# RZ/A1H register map
Vendor: Renesas
Registers are 32-bit, read-write, reset 0x0 unless marked. A register's access mark holds for its fields unless they carry their own. Offsets are from the block's base; [hi:lo] are bit positions; {n}, {i} and the like mark numbered series.

## OSTM0
Base 0xFCFEC000
Same registers: OSTM1 0xFCFEC400
0x00 CMP — OSTMnCMP
0x04 CNT — OSTMnCNT
0x10 TE 8-bit — OSTMnTE
  [0] TE
    0=DISABLE (Counter disabled); 1=ENABLE (Counter enabled)
0x14 TS 8-bit — OSTMnTS
  [0] TS
    0=NOP (No effect); 1=START (Starts the counter and sets TE = 1)
0x18 TT 8-bit — OSTMnTT
  [0] TT
    0=NOP (No effect); 1=STOP (Stops the counter and clears the TE bit)
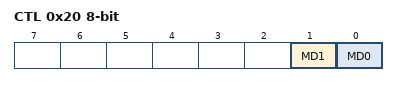
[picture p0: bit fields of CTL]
0x20 CTL 8-bit — OSTMnCTL
  [1] MD1
    0=INTERVAL_TIMER (Interval timer mode); 1=FREE_RUNNING_COMPARISON (Free-running comparison mode)
  [0] MD0

## PFV0
Base 0xE8205000
Same registers: PFV1 0xE8205800
0x00 PFVCR
0x04 PFVICR
0x08 PFVISR
{0x20+4i} PFVID{i} (i=0..7)
{0x40+4i} PFVOD{i} (i=0..7)
0x64 PFVIFSR
0x68 PFVOFSR
0x6C PFVACR
0x70 PFV_MTX_MODE
0x74 PFV_MTX_YG_ADJ0
0x78 PFV_MTX_YG_ADJ1
0x7C PFV_MTX_CBB_ADJ0
0x80 PFV_MTX_CBB_ADJ1
0x84 PFV_MTX_CRR_ADJ0
0x88 PFV_MTX_CRR_ADJ1
0x8C PFVSZR

## PWM
Base 0xFCFF5004
0x02 PWBTCR 8-bit
0xDC PWCR_1 8-bit
0xE0 PWPR_1 8-bit
0xE2 PWCYR_1 16-bit
0xE4 PWBFR_1A 16-bit
0xE6 PWBFR_1C 16-bit
0xE8 PWBFR_1E 16-bit
0xEA PWBFR_1G 16-bit
0xEC PWCR_2 8-bit
0xF0 PWPR_2 8-bit
0xF2 PWCYR_2 16-bit
0xF4 PWBFR_2A 16-bit
0xF6 PWBFR_2C 16-bit
0xF8 PWBFR_2E 16-bit
0xFA PWBFR_2G 16-bit

## RIIC0
Base 0xFCFEE000
Same registers: RIIC1 0xFCFEE400, RIIC2 0xFCFEE800, RIIC3 0xFCFEEC00
0x00 CR1 — RIICnCR1
0x04 CR2 — RIICnCR2
{0x4+4i} MR{i} (i=1..3) — RIICnMR{i}
0x14 FER — RIICnFER
0x18 SER — RIICnSER
0x1C IER — RIICnIER
0x20 SR1 — RIICnSR1
0x24 SR2 — RIICnSR2
{0x28+4i} SAR{i} (i=0..2) — RIICnSAR{i}
0x34 BRL — RIICnBRL
0x38 BRH — RIICnBRH
0x3C DRT — RIICnDRT
0x40 DRR — RIICnDRR

## ROMDEC
Base 0xE8005000
0x00 CROMEN 8-bit
0x01 CROMSY0 8-bit
0x02 CROMCTL0 8-bit
0x03 CROMCTL1 8-bit
{0x2+i} CROMCTL{i} 8-bit (i=3..5)
0x08 CROMST0 8-bit
0x09 CROMST1 8-bit
{0x8+i} CROMST{i} 8-bit (i=3..6)
{0x14+i} CBUFST{i} 8-bit (i=0..2)
{0x18+i} HEAD{i:02} 8-bit (i=0..3)
{0x1C+i} SHEAD{i:02} 8-bit (i=0..7)
{0x10+i} HEAD{i} 8-bit (i=20..23)
{0x14+i} SHEAD{i} 8-bit (i=20..27)
{0x40+i} CBUFCTL{i} 8-bit (i=0..3)
0x45 CROMST0M 8-bit
0x100 RST 8-bit — ROMDECRST
0x101 RSTSTAT 8-bit
0x102 SSI 8-bit
0x108 INTHOLD 8-bit
0x109 INHINT 8-bit
0x200 STRMDIN0 16-bit
0x202 STRMDIN2 16-bit
0x204 STRMDOUT0 16-bit

## RSCAN0
Base 0xE803A000
{0x0+0x10*i} C{i}CFG (i=0..4)
{0x4+0x10*i} C{i}CTR (i=0..4)
{0x8+0x10*i} C{i}STS (i=0..4)
{0xC+0x10*i} C{i}ERFL (i=0..4)
0x84 GCFG
0x88 GCTR
0x8C GSTS
0x90 GERFL
0x94 GTSC
0x98 GAFLECTR
0x9C GAFLCFG0
0xA0 GAFLCFG1
0xA4 RMNB
{0xA8+4i} RMND{i} (i=0..2)
{0xB8+4i} RFCC{i} (i=0..7)
{0xD8+4i} RFSTS{i} (i=0..7)
{0xF8+4i} RFPCTR{i} (i=0..7)
{0x118+4i} CFCC{i} (i=0..14)
{0x178+4i} CFSTS{i} (i=0..14)
{0x1D8+4i} CFPCTR{i} (i=0..14)
0x238 FESTS
0x23C FFSTS
0x240 FMSTS
0x244 RFISTS
0x248 CFRISTS
0x24C CFTISTS
{0x250+i} TMC{i} 8-bit (i=0..79)
{0x2D0+i} TMSTS{i} 8-bit (i=0..79)
{0x350+4i} TMTRSTS{i} (i=0..2)
{0x360+4i} TMTARSTS{i} (i=0..2)
{0x370+4i} TMTCSTS{i} (i=0..2)
{0x380+4i} TMTASTS{i} (i=0..2)
{0x390+4i} TMIEC{i} (i=0..2)
{0x3A0+4i} TXQCC{i} (i=0..4)
{0x3C0+4i} TXQSTS{i} (i=0..4)
{0x3E0+4i} TXQPCTR{i} (i=0..4)
{0x400+4i} THLCC{i} (i=0..4)
{0x420+4i} THLSTS{i} (i=0..4)
{0x440+4i} THLPCTR{i} (i=0..4)
0x460 GTINTSTS0
0x464 GTINTSTS1
0x468 GTSTCFG
0x46C GTSTCTR
0x47C GLOCKK
{0x500+0x10*i} GAFLID{i} (i=0..15)
{0x504+0x10*i} GAFLM{i} (i=0..15)
{0x508+0x10*i} GAFLP{i:02} (i=0..9)
0x50C GAFLP10
0x51C GAFLP11
0x52C GAFLP12
0x53C GAFLP13
0x54C GAFLP14
0x55C GAFLP15
{0x46C+0x10*i} GAFLP{i} (i=16..19)
0x5A8 GAFLP010
0x5AC GAFLP110
0x5B8 GAFLP011
0x5BC GAFLP111
0x5C8 GAFLP012
0x5CC GAFLP112
0x5D8 GAFLP013
0x5DC GAFLP113
0x5E8 GAFLP014
0x5EC GAFLP114
0x5F8 GAFLP015
0x5FC GAFLP115
{0x600+0x10*i} RMID{i} (i=0..79)
{0x604+0x10*i} RMPTR{i} (i=0..79)
{0x608+0x10*i} RMDF{i:02} (i=0..9)
0x60C RMDF10
0x61C RMDF11
0x62C RMDF12
0x63C RMDF13
0x64C RMDF14
0x65C RMDF15
0x66C RMDF16
0x67C RMDF17
0x68C RMDF18
0x69C RMDF19
0x6A8 RMDF010
0x6AC RMDF110
0x6B8 RMDF011
0x6BC RMDF111
0x6C8 RMDF012
0x6CC RMDF112
0x6D8 RMDF013
0x6DC RMDF113
0x6E8 RMDF014
0x6EC RMDF114
0x6F8 RMDF015
0x6FC RMDF115
0x708 RMDF016
0x70C RMDF116
0x718 RMDF017
0x71C RMDF117
0x728 RMDF018
0x72C RMDF118
{0x608+0x10*i} RMDF{i:03} (i=19..79)
0x73C RMDF119
0x74C RMDF120
0x75C RMDF121
0x76C RMDF122
0x77C RMDF123
0x78C RMDF124
0x79C RMDF125
0x7AC RMDF126
0x7BC RMDF127
0x7CC RMDF128
0x7DC RMDF129
0x7EC RMDF130
0x7FC RMDF131
0x80C RMDF132
0x81C RMDF133
0x82C RMDF134
0x83C RMDF135
0x84C RMDF136
0x85C RMDF137
0x86C RMDF138
0x87C RMDF139
0x88C RMDF140
0x89C RMDF141
0x8AC RMDF142
0x8BC RMDF143
0x8CC RMDF144
0x8DC RMDF145
0x8EC RMDF146
0x8FC RMDF147
0x90C RMDF148
0x91C RMDF149
0x92C RMDF150
0x93C RMDF151
0x94C RMDF152
0x95C RMDF153
0x96C RMDF154
0x97C RMDF155
0x98C RMDF156
0x99C RMDF157
0x9AC RMDF158
0x9BC RMDF159
0x9CC RMDF160
0x9DC RMDF161
0x9EC RMDF162
0x9FC RMDF163
0xA0C RMDF164
0xA1C RMDF165
0xA2C RMDF166
0xA3C RMDF167
0xA4C RMDF168
0xA5C RMDF169
0xA6C RMDF170
0xA7C RMDF171
0xA8C RMDF172
0xA9C RMDF173
0xAAC RMDF174
0xABC RMDF175
0xACC RMDF176
0xADC RMDF177
0xAEC RMDF178
0xAFC RMDF179
{0xE00+0x10*i} RFID{i} (i=0..7)
{0xE04+0x10*i} RFPTR{i} (i=0..7)
{0xE08+0x10*i} RFDF{i:02} (i=0..7)
{0xD6C+0x10*i} RFDF{i} (i=10..17)
{0xE80+0x10*i} CFID{i} (i=0..14)
{0xE84+0x10*i} CFPTR{i} (i=0..14)
{0xE88+0x10*i} CFDF{i:02} (i=0..9)
0xE8C CFDF10
0xE9C CFDF11
0xEAC CFDF12
0xEBC CFDF13
0xECC CFDF14
{0xDEC+0x10*i} CFDF{i} (i=15..19)
0xF28 CFDF010
{0x84C+0x10*i} CFDF{i} (i=110..114)
0xF38 CFDF011
0xF48 CFDF012
0xF58 CFDF013
0xF68 CFDF014
{0x1000+0x10*i} TMID{i} (i=0..79)
{0x1004+0x10*i} TMPTR{i} (i=0..79)
{0x1008+0x10*i} TMDF{i:02} (i=0..9)
0x100C TMDF10
0x101C TMDF11
0x102C TMDF12
0x103C TMDF13
0x104C TMDF14
0x105C TMDF15
0x106C TMDF16
0x107C TMDF17
0x108C TMDF18
0x109C TMDF19
0x10A8 TMDF010
{0x9CC+0x10*i} TMDF{i} (i=110..179)
0x10B8 TMDF011
0x10C8 TMDF012
0x10D8 TMDF013
0x10E8 TMDF014
0x10F8 TMDF015
0x1108 TMDF016
0x1118 TMDF017
0x1128 TMDF018
{0x1008+0x10*i} TMDF{i:03} (i=19..79)
{0x1800+4i} THLACC{i} (i=0..4)
